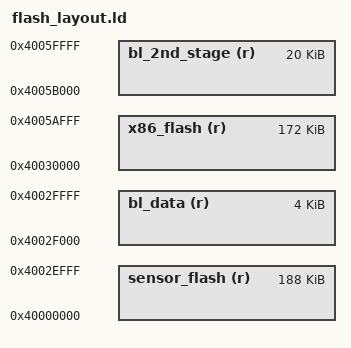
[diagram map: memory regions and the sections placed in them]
/*
 * Copyright (c) 2017, Intel Corporation
 * All rights reserved.
 *
 * Redistribution and use in source and binary forms, with or without
 * modification, are permitted provided that the following conditions are met:
 *
 * 1. Redistributions of source code must retain the above copyright notice,
 *    this list of conditions and the following disclaimer.
 * 2. Redistributions in binary form must reproduce the above copyright notice,
 *    this list of conditions and the following disclaimer in the documentation
 *    and/or other materials provided with the distribution.
 * 3. Neither the name of the Intel Corporation nor the names of its
 *    contributors may be used to endorse or promote products derived from this
 *    software without specific prior written permission.
 *
 * THIS SOFTWARE IS PROVIDED BY THE COPYRIGHT HOLDERS AND CONTRIBUTORS "AS IS"
 * AND ANY EXPRESS OR IMPLIED WARRANTIES, INCLUDING, BUT NOT LIMITED TO, THE
 * IMPLIED WARRANTIES OF MERCHANTABILITY AND FITNESS FOR A PARTICULAR PURPOSE
 * ARE DISCLAIMED. IN NO EVENT SHALL THE INTEL CORPORATION OR CONTRIBUTORS BE
 * LIABLE FOR ANY DIRECT, INDIRECT, INCIDENTAL, SPECIAL, EXEMPLARY, OR
 * CONSEQUENTIAL DAMAGES (INCLUDING, BUT NOT LIMITED TO, PROCUREMENT OF
 * SUBSTITUTE GOODS OR SERVICES; LOSS OF USE, DATA, OR PROFITS; OR BUSINESS
 * INTERRUPTION) HOWEVER CAUSED AND ON ANY THEORY OF LIABILITY, WHETHER IN
 * CONTRACT, STRICT LIABILITY, OR TORT (INCLUDING NEGLIGENCE OR OTHERWISE)
 * ARISING IN ANY WAY OUT OF THE USE OF THIS SOFTWARE, EVEN IF ADVISED OF THE
 * POSSIBILITY OF SUCH DAMAGE.
 */

/*
 * This Linker File adds a different memory mapping where 2nd-stage added at
 * the end of flash1.
 */

MEMORY
{
	/* Flash Memmory Map */
	sensor_flash (r): ORIGIN = 0x40000000, LENGTH = 188K
	bl_data (r)	: ORIGIN = 0x4002f000, LENGTH = 4K
	x86_flash (r)	: ORIGIN = 0x40030000, LENGTH = 172K
	bl_2nd_stage (r): ORIGIN = 0x4005b000, LENGTH = 20K
}

__sensor_flash_start = ORIGIN(sensor_flash);
__x86_flash_start = ORIGIN(x86_flash);
__bl_data_start = ORIGIN(bl_data);
__bl_2nd_stage_start = ORIGIN(bl_2nd_stage);
